VERSION "1"

NS_ :

BS_:

BU_: Ecu1 Ecu2

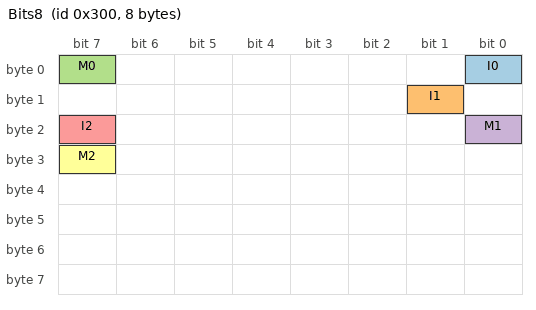
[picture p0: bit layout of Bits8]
BO_ 768 Bits8: 8 Ecu1
 SG_ I0 : 0|1@1+ (1,0) [0|1] "" Ecu2
 SG_ I1 : 9|1@1+ (1,0) [0|1] "" Ecu2
 SG_ M0 : 7|1@0+ (1,0) [0|1] "" Ecu2
 SG_ M1 : 16|1@0+ (1,0) [0|1] "" Ecu2
 SG_ I2 : 23|1@1+ (1,0) [0|1] "" Ecu2
 SG_ M2 : 31|1@0+ (1,0) [0|1] "" Ecu2
